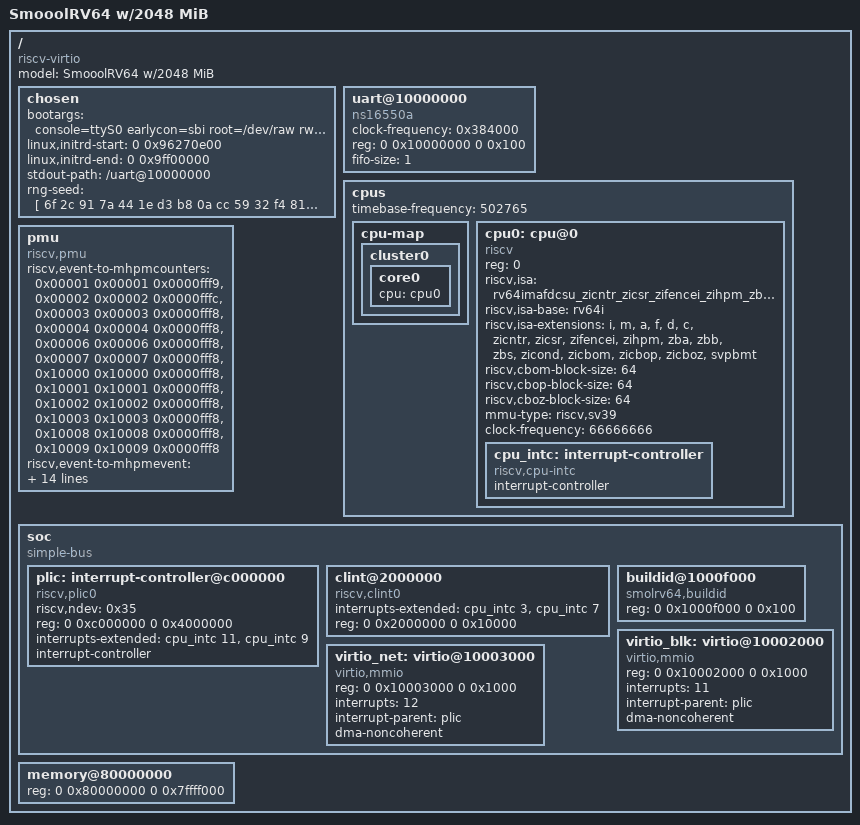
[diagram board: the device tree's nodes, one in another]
/dts-v1/;

/ {
	#address-cells = <2>;
	#size-cells = <2>;
	compatible = "riscv-virtio";
	model = "SmooolRV64 w/2048 MiB";  // gb5 initramfs variant

	chosen {
		/* Boot the Geekbench 5 initramfs: busybox runs /etc/init.d/S90geekbench,
		   which execs /root/gb/geekbench_riscv64 -- so AES-XTS, the first
		   workload and the one that fails validation, starts seconds after
		   boot instead of ~10 min of systemd/cloud-init. No network needed. */
		bootargs = "console=ttyS0 earlycon=sbi root=/dev/raw rw ignore_loglevel random.trust_bootloader=on";
		linux,initrd-start = <0 0x96270e00>;
		linux,initrd-end   = <0 0x9ff00000>;
		stdout-path = "/uart@10000000";

		/* Development-only static seed: replace with per-boot random bytes later. */
		rng-seed = [
			6f 2c 91 7a 44 1e d3 b8
			0a cc 59 32 f4 81 25 9d
			e7 10 ba 6c 38 5f 02 c1
			93 d4 76 af 20 8b ee 41
			15 62 9a cd 57 03 b4 f8
			80 2d 11 6e a9 4c 73 05
			dc 37 f1 98 24 bb 60 0f
			4a e2 7d 36 c5 19 8c a0
		];
	};

	uart@10000000 {
		clock-frequency = <0x384000>;
		reg = <0 0x10000000 0 0x100>;
		compatible = "ns16550a";
		fifo-size = <1>;
	};

	cpus {
		#address-cells = <1>;
		#size-cells = <0>;
                timebase-frequency = <502765>;  /* REAL rate = PROBE_CLK_HZ/SCALE_DIV, not 501253: SCALE_DIV is an integer. DIV8=72 -> 111,111,104/221 = 502765. Was 501253 (the exact value for the 66.67MHz era), i.e. 0.302% fast on every FPGA run since the 111MHz milestone. Checked by tools/check-dts-timebase.py. */  /* REAL rate: probe_clk 66.67MHz / CLINT SCALE_DIV 133. Was 20050120, a 40x "deadline probe" lie (4583ba4) that made every kernel deadline 40x longer in real time -- healthy boots looked permanently stalled and the timer appeared to storm. MUST track probe/soc_top.v clint SCALE_DIV. */

		cpu-map {
			cluster0 {
				core0 {
					cpu = <&cpu0>;
				};
			};
		};

		cpu0: cpu@0 {
			device_type = "cpu";
			reg = <0>;
			status = "okay";
			compatible = "riscv";
			riscv,isa = "rv64imafdcsu_zicntr_zicsr_zifencei_zihpm_zba_zbb_zbs_zicond_zicbom_zicbop_zicboz_svpbmt";
			riscv,isa-base = "rv64i";
			riscv,isa-extensions = "i", "m", "a", "f", "d", "c",
				"zicntr", "zicsr", "zifencei", "zihpm",
				"zba", "zbb", "zbs", "zicond",
				"zicbom", "zicbop", "zicboz", "svpbmt";
			riscv,cbom-block-size = <64>;
			riscv,cbop-block-size = <64>;
			riscv,cboz-block-size = <64>;
			mmu-type = "riscv,sv39";
			clock-frequency = <66666666>;

			cpu_intc: interrupt-controller {
				#interrupt-cells = <1>;
				interrupt-controller;
				compatible = "riscv,cpu-intc";
			};
		};
	};

	pmu {
		compatible = "riscv,pmu";
		riscv,event-to-mhpmcounters =
			<0x00001 0x00001 0x0000fff9>,
			<0x00002 0x00002 0x0000fffc>,
			<0x00003 0x00003 0x0000fff8>,
			<0x00004 0x00004 0x0000fff8>,
			<0x00006 0x00006 0x0000fff8>,
			<0x00007 0x00007 0x0000fff8>,
			<0x10000 0x10000 0x0000fff8>,
			<0x10001 0x10001 0x0000fff8>,
			<0x10002 0x10002 0x0000fff8>,
			<0x10003 0x10003 0x0000fff8>,
			<0x10008 0x10008 0x0000fff8>,
			<0x10009 0x10009 0x0000fff8>;
		riscv,event-to-mhpmevent =
			<0x00001 0x00000000 0x00000001>,
			<0x00002 0x00000000 0x00000002>,
			<0x00003 0x00000000 0x00000100>,
			<0x00004 0x00000000 0x00000102>,
			<0x00006 0x00000000 0x00000005>,   /* BRANCH_MISSES -> redirect count */
			<0x00007 0x00000000 0x00000202>,
			/* L1D and L1I were SWAPPED here: 0x1000x (L1-dcache) pointed at the
			   I-cache events 0x011x and 0x1000[89] (L1-icache) at the D-cache
			   events 0x010x, so `perf stat -e L1-dcache-loads` reported I$ traffic.
			   The cache counters do not split read vs write, so the write variants
			   stay mapped to unimplemented codes (they read 0 rather than lie). */
			<0x10000 0x00000000 0x00000100>,   /* L1D read access  -> D$ access */
			<0x10001 0x00000000 0x00000102>,   /* L1D read miss    -> D$ miss   */
			<0x10002 0x00000000 0x00000111>,   /* L1D write access -> n/a       */
			<0x10003 0x00000000 0x00000113>,   /* L1D write miss   -> n/a       */
			<0x10008 0x00000000 0x00000110>,   /* L1I read access  -> I$ access */
			<0x10009 0x00000000 0x00000112>;   /* L1I read miss    -> I$ miss   */
		riscv,raw-event-to-mhpmcounters =
			<0x00000000 0x00000000 0xffffffff 0xffff0000 0x0000fff8>;
	};

	soc {
		#address-cells = <2>;
		#size-cells = <2>;
		compatible = "simple-bus";
		ranges;

		plic: interrupt-controller@c000000 {
			riscv,ndev = <0x35>;
			reg = <0 0xc000000 0 0x4000000>;
			interrupts-extended = <&cpu_intc 11 &cpu_intc 9>;
			interrupt-controller;
			compatible = "riscv,plic0";
			#interrupt-cells = <1>;
			#address-cells = <0>;
		};

		clint@2000000 {
			interrupts-extended = <&cpu_intc 3 &cpu_intc 7>;
			reg = <0 0x2000000 0 0x10000>;
			compatible = "riscv,clint0";
		};

		buildid@1000f000 {
			compatible = "smolrv64,buildid";
			reg = <0 0x1000f000 0 0x100>;
		};

		virtio_blk: virtio@10002000 {
			compatible = "virtio,mmio";
			reg = <0 0x10002000 0 0x1000>;
			interrupts = <11>;
			interrupt-parent = <&plic>;
			dma-noncoherent;
			status = "okay";
		};

		virtio_net: virtio@10003000 {
			compatible = "virtio,mmio";
			reg = <0 0x10003000 0 0x1000>;
			interrupts = <12>;
			interrupt-parent = <&plic>;
			dma-noncoherent;
			status = "okay";
		};
	};

	memory@80000000 {
		device_type = "memory";
		reg = <0 0x80000000 0 0x7ffff000>; // 2 GiB MiB
	};
};
